# nrf5340_application register map
Vendor: Nordic Semiconductor; Series: nrf53; File version: 1
CPU: CM33 r0p4, little endian, MPU, FPU, 3 interrupt priority bits, 69 interrupts
Registers are 32-bit, read-write, reset 0x0 unless marked. A register's access mark holds for its fields unless they carry their own. Offsets are from the block's base; [hi:lo] are bit positions; lines under a group give offsets from that group; {n}, {i} and the like mark numbered series.

## NVMC_NS — Non-volatile memory controller 0
Base 0x40039000; alternate view of KMU_NS
Same registers: NVMC_S 0x50039000 (alternate view of KMU_S)
0x400 READY ro reset 0x1 — Ready flag
  [0] READY — NVMC is ready or busy
    0=Busy (NVMC is busy (on-going write or erase operation)); 1=Ready (NVMC is ready)
0x408 READYNEXT ro reset 0x1 — Ready flag
  [0] READYNEXT — NVMC can accept a new write operation
    0=Busy (NVMC cannot accept any write operation); 1=Ready (NVMC is ready)
0x504 CONFIG — Configuration register
  [2:0] WEN — Program memory access mode. It is strongly recommended to only activate erase and write modes when they are actively used. Enabling write or erase will invalidate the cache and keep it invalidated.
    0=Ren (Read only access); 1=Wen (Write enabled); 2=Een (Erase enabled); 4=PEen (Partial erase enabled)
0x50C ERASEALL wo — Register for erasing all non-volatile user memory
  [0] ERASEALL — Erase all non-volatile memory including UICR registers. Note that erasing must be enabled by setting CONFIG.WEN = Een before the non-volatile memory can be erased.
    0=NoOperation; 1=Erase (Start chip erase)
0x51C ERASEPAGEPARTIALCFG reset 0xA — Register for partial erase configuration
  [6:0] DURATION — Duration of the partial erase in milliseconds
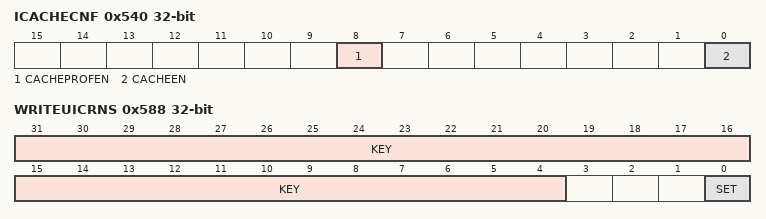
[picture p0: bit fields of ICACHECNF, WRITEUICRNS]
0x540 ICACHECNF — I-code cache configuration register
  [8] CACHEPROFEN — Cache profiling enable
    0=Disabled (Disable cache profiling); 1=Enabled (Enable cache profiling)
  [0] CACHEEN — Cache enable
    0=Disabled (Disable cache. Invalidates all cache entries.); 1=Enabled (Enable cache)
0x548 IHIT — I-code cache hit counter
  [31:0] HITS — Number of cache hits Write zero to clear
0x54C IMISS — I-code cache miss counter
  [31:0] MISSES — Number of cache misses Write zero to clear
0x584 CONFIGNS — Unspecified
  [1:0] WEN — Program memory access mode. It is strongly recommended to only activate erase and write modes when they are actively used. Enabling write or erase will invalidate the cache and keep it invalidated.
    0=Ren (Read only access); 1=Wen (Write enabled); 2=Een (Erase enabled)
0x588 WRITEUICRNS wo — Non-secure APPROTECT enable register
  [31:4] KEY — Key to write in order to validate the write operation
    0xAFBE5A7=Keyvalid (Key value)
  [0] SET — Allow non-secure code to set APPROTECT
    1=Set (Set value)

## CRYPTOCELL_S — ARM TrustZone CryptoCell register interface
Base 0x50844000
0x500 ENABLE — Enable CRYPTOCELL subsystem.
  [0] ENABLE — Enable or disable the CRYPTOCELL subsystem.
    0=Disabled (CRYPTOCELL subsystem disabled.); 1=Enabled (CRYPTOCELL subsystem enabled.)

## VMC_NS — Volatile Memory controller 0
Base 0x40081000
Same registers: VMC_S 0x50081000
{0x600+0x10*i} RAM[{i}] (i=0..7) group — Unspecified
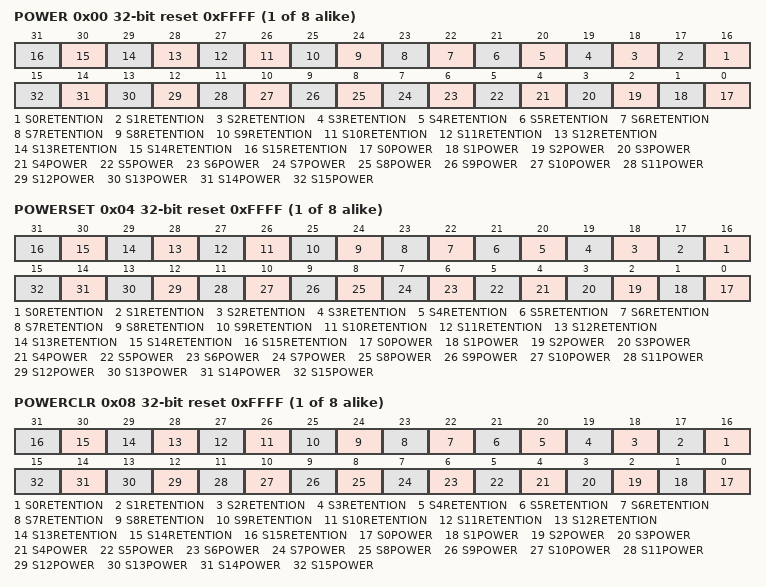
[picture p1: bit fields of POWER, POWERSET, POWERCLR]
  0x00 POWER reset 0xFFFF — Description cluster: RAM[n] power control register
    [all] fields
      0=Off; 1=On
    [n+16] S{n}RETENTION (n=0..15) — Keep retention on RAM section S{n} of RAM[n] when RAM section is switched off
    [n] S{n}POWER (n=0..15) — Keep RAM section S{n} of RAM[n] on or off in System ON mode
  0x04 POWERSET reset 0xFFFF — Description cluster: RAM[n] power control set register
    [all] fields
      1=On
    [n+16] S{n}RETENTION (n=0..15) — Keep retention on RAM section S{n} of RAM[n] when RAM section is switched off
    [n] S{n}POWER (n=0..15) — Keep RAM section S{n} of RAM[n] on or off in System ON mode
  0x08 POWERCLR reset 0xFFFF — Description cluster: RAM[n] power control clear register
    [all] fields
      1=Off
    [n+16] S{n}RETENTION (n=0..15) — Keep retention on RAM section S{n} of RAM[n] when RAM section is switched off
    [n] S{n}POWER (n=0..15) — Keep RAM section S{n} of RAM[n] on or off in System ON mode
